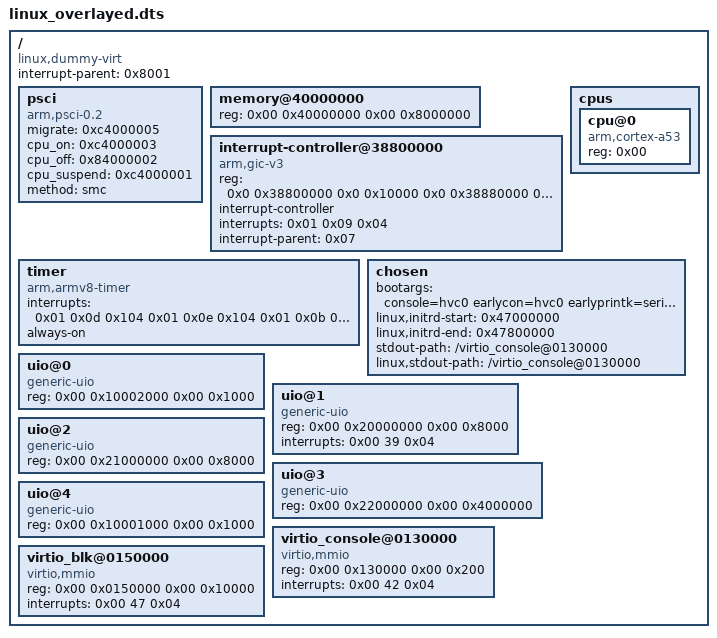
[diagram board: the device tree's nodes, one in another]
/dts-v1/;

/ {
	interrupt-parent = <0x8001>;
	#size-cells = <0x02>;
	#address-cells = <0x02>;
	compatible = "linux,dummy-virt";

	psci {
		migrate = <0xc4000005>;
		cpu_on = <0xc4000003>;
		cpu_off = <0x84000002>;
		cpu_suspend = <0xc4000001>;
		method = "smc";
		compatible = "arm,psci-0.2\0arm,psci";
	};

    memory@40000000 {
		reg = <0x00 0x40000000 0x00 0x8000000>;
		device_type = "memory";
	};

	interrupt-controller@38800000 {
		compatible = "arm,gic-v3";
		reg = <0x0 0x38800000 0x0 0x10000 0x0 0x38880000 0x0 0xc0000 0x0 0x31000000 0x0 0x2000 0x0 0x31010000 0x0 0x2000 0x0 0x31020000 0x0 0x2000>;
		#interrupt-cells = <0x03>;
		interrupt-controller;
		interrupts = <0x01 0x09 0x04>;
		interrupt-parent = <0x07>;
		phandle = <0x8001>;
	};

	cpus {
		#size-cells = <0x00>;
		#address-cells = <0x01>;

		cpu@0 {
			reg = <0x00>;
			compatible = "arm,cortex-a53";
			device_type = "cpu";
		};
	};

	timer {
		interrupts = <0x01 0x0d 0x104 0x01 0x0e 0x104 0x01 0x0b 0x104 0x01 0x0a 0x104>;
		always-on;
		compatible = "arm,armv8-timer\0arm,armv7-timer";
	};

	chosen {
		bootargs = "console=hvc0 earlycon=hvc0 earlyprintk=serial debug loglevel=0 uio_pdrv_genirq.of_id=generic-uio";
		linux,initrd-start = <0x47000000>;
		linux,initrd-end = <0x47800000>;
        stdout-path = "/virtio_console@0130000";
        linux,stdout-path = "/virtio_console@0130000";
	};

    // Filesystem Driver VM specific UIO devices.

    // All of these paddrs are arbitrarily chosen.
    // The only consideration is that you don't hit any other
    // physical device region or the guest RAM.
    uio@0 {
        // config data
        compatible = "generic-uio\0vmfs_config";
        reg = <0x00 0x10002000 0x00 0x1000>;
    };

    uio@1 {
        // fs_command_queue and client IRQ
        compatible = "generic-uio\0vmfs_command";
        reg = <0x00 0x20000000 0x00 0x8000>;
        interrupts = <0x00 39 0x04>;
        // IRQ = uKit 71 (39 + 32)
    };

    uio@2 {
        // fs_completion_queue
        compatible = "generic-uio\0vmfs_completion";
        reg = <0x00 0x21000000 0x00 0x8000>;
    };

    uio@3 {
        // shared_fs_data
        compatible = "generic-uio\0vmfs_data";
        reg = <0x00 0x22000000 0x00 0x4000000>;
    };

    uio@4 {
        // guest to vmm fault region, this must be unmapped in SDF.
        compatible = "generic-uio\0vmfs_fault";
        reg = <0x00 0x10001000 0x00 0x1000>;
    };

	virtio_console@0130000 {
		compatible = "virtio,mmio";
		reg = <0x00 0x130000 0x00 0x200>;
		interrupts = <0x00 42 0x04>;
	};
	
	virtio_blk@0150000 {
		compatible = "virtio,mmio";
		reg = <0x00 0x0150000 0x00 0x10000>;
		interrupts = <0x00 47 0x04>;
		// IRQ number = 79
	};
};
